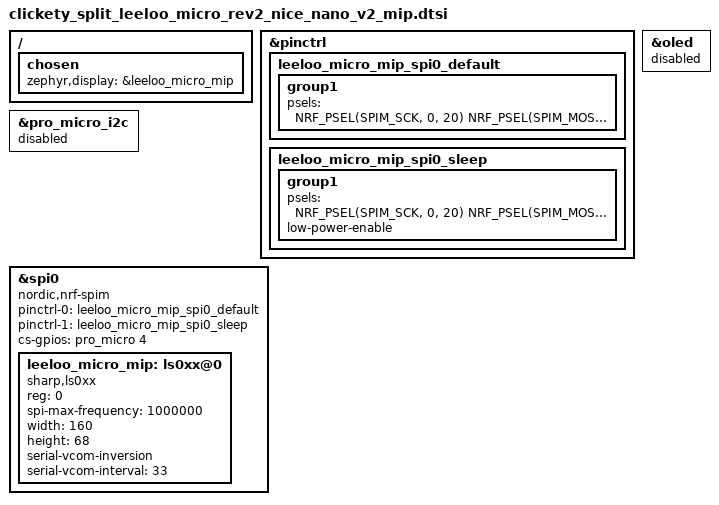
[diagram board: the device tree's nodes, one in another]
/*
 * Copyright (c) 2026 Clickety Split Ltd.
 * SPDX-License-Identifier: MIT
 */

#include <dt-bindings/gpio/gpio.h>

/ {
    chosen {
        zephyr,display = &leeloo_micro_mip;
    };
};

&pinctrl {
    leeloo_micro_mip_spi0_default:
        leeloo_micro_mip_spi0_default {
        group1 {
            psels = <
                NRF_PSEL(SPIM_SCK, 0, 20)
                NRF_PSEL(SPIM_MOSI, 0, 17)
            >;
        };
    };

    leeloo_micro_mip_spi0_sleep:
        leeloo_micro_mip_spi0_sleep {
        group1 {
            psels = <
                NRF_PSEL(SPIM_SCK, 0, 20)
                NRF_PSEL(SPIM_MOSI, 0, 17)
            >;
            low-power-enable;
        };
    };
};

/*
 * The Leeloo-Micro base DTSI includes an SSD1306 OLED on pro_micro_i2c.
 * Disable both the OLED child and its bus before configuring peripheral
 * zero as the MIP display SPI bus.
 */
&oled {
    status = "disabled";
};

&pro_micro_i2c {
    status = "disabled";
};

&spi0 {
    compatible = "nordic,nrf-spim";
    status = "okay";

    pinctrl-0 = <&leeloo_micro_mip_spi0_default>;
    pinctrl-1 = <&leeloo_micro_mip_spi0_sleep>;
    pinctrl-names = "default", "sleep";

    cs-gpios = <&pro_micro 4 GPIO_ACTIVE_HIGH>;

    leeloo_micro_mip: ls0xx@0 {
        compatible = "sharp,ls0xx";
        status = "okay";

        reg = <0>;
        spi-max-frequency = <1000000>;

        width = <160>;
        height = <68>;

        serial-vcom-inversion;
        serial-vcom-interval = <33>;
    };
};
